# MSS_TOPRCM register map
Vendor: Texas Instruments
Peripheral module from a debugger description file (folder radar).
Registers are 32-bit, read-write, no defined reset value unless marked. A register's access mark holds for its fields unless they carry their own. Offsets are as the file gives them; lines under a group give offsets from that group; [hi:lo] are bit positions; {n}, {i} and the like mark numbered series; 'fields as' and 'values as' point back to an identical list; <NAME> marks a mode.

## MSS_TOPRCM
0x08 BSSCTL — Control Signals to BSS
  [31:24] BSSCPUHALT — Halt BSS CR4, To halt : either 3:0 should be 0xD or 7:4 should be 0xA One should Halt the processor before releasing BSS reset.
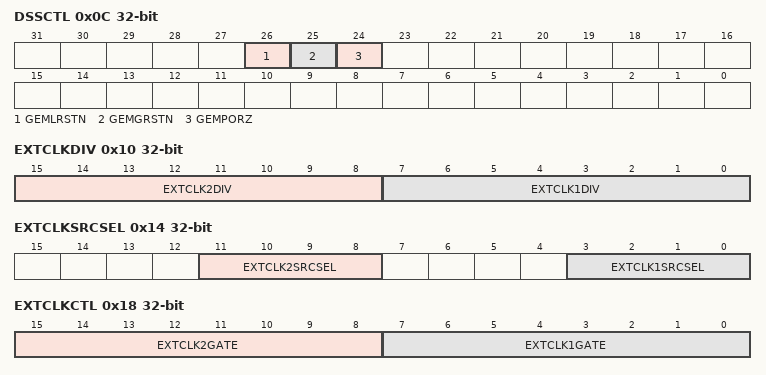
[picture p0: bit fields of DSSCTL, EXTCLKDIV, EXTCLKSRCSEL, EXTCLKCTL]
0x0C DSSCTL — Control Signals to DSS
  [26] GEMLRSTN — DSP Local Reset value that will be propagated to the DSP when the DSP Power FSM has switched the DSP on. 0x0 : Reset is asserted 0x1 : Reset is deasserted This value is to be set by SW to 0x1 once initially before the DSP is powered on and is not expected to be changed. All Reset toggling for the DSP is exepcted to be done via the DSP Power FSM and the DSP STC FSM
  [25] GEMGRSTN — DSP Global Reset value that will be propagated to the DSP when the DSP Power FSM has switched the DSP on. 0x0 : Reset is asserted 0x1 : Reset is deasserted This value is to be set by SW to 0x1 once initially before the DSP is powered on and is not expected to be changed. All Reset toggling for the DSP is exepcted to be done via the DSP Power FSM and the DSP STC FSM
  [24] GEMPORZ — DSP Por Reset value that will be propagated to the DSP when the DSP Power FSM has switched the DSP on. 0x0 : Reset is asserted 0x1 : Reset is deasserted This value is to be set by SW to 0x1 once initially before the DSP is powered on and is not expected to be changed. All Reset toggling for the DSP is exepcted to be done via the DSP Power FSM and the DSP STC FSM
0x10 EXTCLKDIV — Clock divide value for MCU_CLKOUT and PMIC_CLKOUT
  [15:8] EXTCLK2DIV — Divide value for clock source ( selected by field EXTCLKSRCSEL in register CLKSRCSEL.) to PMIC_CLKOUT generation logic “0000_0000” => div1 “0000_0001” => div2 | | “1111_1111” => div256 One Should change the divide value before switching to New clock. Switching to New clock is done by progrmming EXTCLK2SRCSEL.
  [7:0] EXTCLK1DIV — Divide value for MCU_CLKOUT (the one going out of chip) source clock selected by field EXTCLKSRCSEL in register CLKSRCSEL. “0000_0000” => div1 “0000_0001” => div2 | | “1111_1111” => div256 One Should change the divide value before switching to New clock. Switching to New clock is done by progrmming EXTCLK1SRCSEL.
0x14 EXTCLKSRCSEL — Clock source select value for MCU_CLKOUT and PMIC_CLKOUT
  [11:8] EXTCLK2SRCSEL — Select clock source for PMIC_CLKOUT generation “000” => CPUCLK from ANA(XTAL 40Mhz or 50 Mhz or 80Mh or 100Mhz/ RCCLK in WU limp mode) “001” => RCCLK (10Mhz) “010” => 600Mhz PLL divided clock “011” => 240Mhz PLL divided clock “100” => RCCLK (10Mhz) “101” => RCCLK (10Mhz) “110” => REFCLK from ANA (40Mhz or 50 Mhz or 80Mh or 100Mhz) “111” => RCCLK
  [3:0] EXTCLK1SRCSEL — Select clock source for MCU_CLKOUT “000” =>CPUCLK from ANA(XTAL 40Mhz or 50 Mhz or 80Mh or 100Mhz/ RCCLK in WU limp mode) “001” => RCCLK (10Mhz) “010” => 600Mhz PLL divided clock “011” => 240Mhz PLL divided clock “100” => RCCLK (10Mhz) “101” => RCCLK (10Mhz) “110” => REFCLK from ANA (40Mhz or 50 Mhz or 80Mh or 100Mhz) “111” => RCCLK
0x18 EXTCLKCTL — Clock gate control for MCU_CLKOUT and PMIC_CLKOUT
  [15:8] EXTCLK2GATE — Pre clock divider gate for PMIC_CLKOUT. Gates the clock before divider. to gate the clock either 3:0 should be 0xD or 7:4 should be 0xA
  [7:0] EXTCLK1GATE — Pre clock divider gate for MCU_CLKOUT. Gates the clock before divider. to gate the clock either 3:0 should be 0xD or 7:4 should be 0xA
0x1C SOFTSYSRST — Software triggered Warm Reset
  [7:0] SOFTSYSRST — Write 0xAD to trigger warm reset to the chip.
0x20 WDRSTEN — Issue Warm reset upon MSS Watch dog reset
  [7:0] WDRSTEN — Write 0xAD to trigger warm reset to the chip upon MSS wdog reset.
0x24 SYSRSTCAUSE ro — Reset cause register
  [3:0] SYSRSTCAUSE — Gives cause of chip reset “1001” : System out of NRESET “1010” : Warm reset because of MSS Wdog. “1100” : Warm reset because of Software trigger- SOFTSYSRST “1000” : External Warm Reset
0x28 SYSRSTCAUSECLR access not given — Clear Reset Cause register
  [7:0] SYSRSTCAUSECLR — Write 0xAD to clear SYSRSTCAUSE..Self clearing
0x34 MISCCAPT ro — Capture required Status values across the chip.
  [31:0] MISCCAPT — 4:0 :TI_EFC_ERR. 00000 : No Error 00001 Time-out 00010 Autoload: Not enough FuseROM data 00011 Autoload: Wrong scan chain signature 00100 Autoload: Interrupted 10100 Program: Dumpword: Test ROM: Interrupted 00101 Autoload: Two-bit error detected 00110 program: Write protect set 00111 Program: Too many data write iterations 01000 Program: Too many control bit iterations 01001 Test unprogrammed FuseROM: Bit set 01010 Redundant repair row 01011 Program: Too many CRA write iterations 01100 Program: Program done 01101 Program: Compare skip 01110 Program: Abort 01111 Program with incorrect key register value 10000 Autoload: FuseROM LASTROW stuck 10010 FuseROM LASTROW stuck 10101 Autoload: one-bit errorDetected 10110 Dump Word: two-bit error Detected 10111 Dump Word: one-bit error Detected 11000 Self-test error detected 11111 - 11001 Not assigned 5: BSS reset got asserted upon setting BSSPRST/BSSRST. 6: DSS reset got asserted upon setting DSSPRST/DSSRST [11:7] : CUST_EFC_ERR.Description same as TI_EFC_ERR
0x38 DCDCCTL0 — PMIC_CLKOUT dethering control
  [31:0] DCDCCTL0 — [26:0] PMIC_CLKOUT Frequency slope value.Unsigned
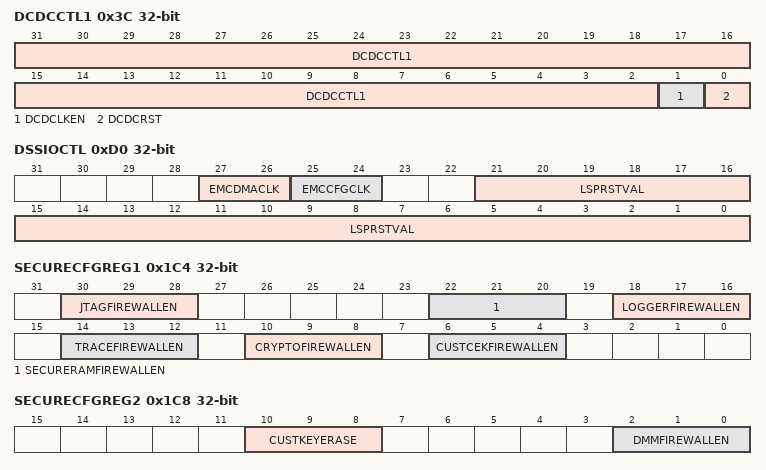
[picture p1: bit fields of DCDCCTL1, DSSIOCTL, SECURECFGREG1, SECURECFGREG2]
0x3C DCDCCTL1 — PMIC_CLKOUT dethering control
  [31:2] DCDCCTL1 — PMIC_CLKOUT dithering control [8] : Frequency accumulation Mode . ‘0’ : Continous mode.’1’ : Staircase mode [9] : ‘1’ Enables dither [23:16] : Minimum frequency threshold [31:24] : Maximum frequency threshold
  [1] DCDCLKEN — PMIC_CLKOUT Enable – Multi Bit
  [0] DCDCRST — PMIC_CLKOUT dithering control block reset (active high) – Multi Bit
0x48 USERMODEEN
  [31:0] USERMODEEN — Write 0XADADADAD to enable user mode write access to TOP RCM space from 0x00 to 0XFF
0x4C LVDSPADCTL0 — LVDS pad control
  [31:0] LVDSPADCTL0 — 0 : pwrdn Control for i_LVDSclk_io_cell 1 : lopwra Control for i_LVDSclk_io_cell 2 : lopwrb Control for i_LVDSclk_io_cell 3 : lpsel Control for i_LVDSclk_io_cell 4 : sub_lvds_en Control for i_LVDSclk_io_cell 5 : hiz_disable Control for i_LVDSclk_io_cell 6 : ext_res_en Control for i_LVDSclk_io_cell 7 : Reserved 8 : pwrdn Control for i_LVDS_tx0_io_cell 9 : lopwra Control for i_LVDS_tx0_io_cell 10 : lopwrb Control for i_LVDS_tx0_io_cell 11 : lpsel Control for i_LVDS_tx0_io_cell 12 : sub_lvds_en Control for i_LVDS_tx0_io_cell 13 : hiz_disable Control for i_LVDS_tx0_io_cell 14 : ext_res_en Control for i_LVDS_tx0_io_cell 15 : Reserved 16 : pwrdn Control for i_LVDS_tx1_io_cell 17 : lopwra Control for i_LVDS_tx1_io_cell 18 : lopwrb Control for i_LVDS_tx1_io_cell 19 : lpsel Control for i_LVDS_tx1_io_cell 20 : sub_lvds_en Control for i_LVDS_tx1_io_cell 21 : hiz_disable Control for i_LVDS_tx1_io_cell 22 : ext_res_en Control for i_LVDS_tx1_io_cell 23 -31 : Reserved
0x50 LVDSPADCTL1 — LVDS pad control
  [31:0] LVDSPADCTL1 — 0- 7 : Reserved 8 : pwrdn Control for i_LVDSfrclk_io_cell 9 : lopwra Control for i_LVDSfrclk_io_cell 10 : lopwrb Control for i_LVDSfrclk_io_cell 11 : lpsel Control for i_LVDSfrclk_io_cell 12 : sub_lvds_en Control for i_LVDSfrclk_io_cell 13 : hiz_disable Control for i_LVDSfrclk_io_cell 14 : ext_res_en Control for i_LVDSfrclk_io_cell 15-23: Reserved 24 : pwrdn Control for lvds_bias_cell 25 : set Control for lvds_bias_cell
0x60 DFTREG0
  [31:0] DFTREG0 — TRM Description: [3:0] : MSS PBIST SELFTEST KEY = 4'b1010 [4] : Reserved [5] : PBIST IP reset control. 1 = reset, 0 = out of reset. The PBIST_SELFTEST_KEY has to enabled in order to program this bit. [31:6] : Write 1'b1 to a bit to configure a particular memory group for Self-Test, and 1'b0 to disable a particular memory group 16XX Description: [3:0] : MSS PBIST SELFTEST KEY = 4'b1010 [4] : Reserved [5] : PBIST IP reset control. 1 = reset, 0 = out of reset. The PBIST_SELFTEST_KEY has to enabled in order to program this bit. [6] : MSS DCAN and CANFD RAMs - Write 1'b1 to configure this memory group for self-test [7] : MSS DMA RAMs - Write 1'b1 to configure this memory group for self-test [8] : MSS VIM RAMs - Write 1'b1 to configure this memory group for self-test [9] : MSS SWBUF RAM - Write 1'b1 to configure this memory group for self-test [10] : MSS TCMAROMs - Write 1'b1 to configure this memory group for self-test [11] : MSS TCMA RAMs - Write 1'b1 to configure this memory group for self-test [12] : MSS TCMB RAMs - Write 1'b1 to configure this memory group for self-test [13] : Reserved [14] : MSS L3SHARED RAMs BANK2 and BANK3 - Write 1'b1 to configure this memory group for self-test [15] : MSS L3SHARED RAMs BANK4 and BANK5 - Write 1'b1 to configure this memory group for self-test [16] : MSS SPIA RAMs - Write 1'b1 to configure this memory group for self-test [17] : MSS SPIB RAMs - Write 1'b1 to configure this memory group for self-test [18] : MSS MBOX RAMs - Write 1'b1 to configure this memory group for self-test [19] : MSS CR4 STC ROM - Write 1'b1 to configure this memory group for self-test [20] : Reserved [21] : Reserved [22] : Reserved [23] : Reserved [24] : DSS ADCBUF RAMs - Write 1'b1 to configure this memory group for self-test [25] : DSS FFTACC RAMs - Write 1'b1 to configure this memory group for self-test [26] : DSS TPCC RAMs - Write 1'b1 to configure this memory group for self-test [27] : DSS CBUF DATA and ECC RAMs - Write 1'b1 to configure this memory group for self-test [28] : Reserved [29] : DSS CQ RAMs- Write 1'b1 to configure this memory group for self-test [30] : BSS TCMAROMs - Write 1'b1 to configure this memory group for self-test [31] : BSS TCMA and TCMB RAMs - Write 1'b1 to configure this memory group for self-test
0x64 DFTREG1
  [31:0] DFTREG1 — TRM Description: [31:0] : Write 1'b1 to a bit to configure a particular memory group for Self-Test, and 1'b0 to disable a particular memory group 16XX Description: [0] : BSS FFT RAMs and ROM - Write 1'b1 to configure this memory group for self-test [1] : BSS VIM RAMs - Write 1'b1 to configure this memory group for self-test [2] : BSS DFE RAMs - Write 1'b1 to configure this memory group for self-test [3] : BSS CR4 STC ROM - Write 1'b1 to configure this memory group for self-test [4] : BSS DFE STC ROM - Write 1'b1 to configure this memory group for self-test [5] : BSS GPADC RAMs - Write 1'b1 to configure this memory group for self-test [12:6] : Reserved [13] : DSS HS and DATA_TR RAMs - Write 1'b1 to configure this memory group for self-test [14] : DSS FIR RAM - Write 1'b1 to configure this memory group for self-test [15] : GEM STC ROM - Write 1'b1 to configure this memory group for self-test [16] : GEM PBIST ROM - Write 1'b1 to configure this memory group for self-test [17] : GEM CPBPM RAMs - Write 1'b1 to configure this memory group for self-test [18] : Reserved [19] : Reserved [19] : MSS SECUREKEY RAM - Write 1'b1 to configure this memory group for self-test [21] : MSS TRACEBUF RAM - Write 1'b1 to configure this memory group for self-test [31:22] : Reserved
0x68 DFTREG2
  [31:0] DFTREG2 — TI Internal Register.Reserved for HW RnD
0x74 DFTREG5
  [31:0] DFTREG5 — TRM Description: [0] : Reserved [4:1] DSP PBIST SELFTEST KEY = 4'b1010 [8:5]: Sub-system level memory Self-Test power clock gate enable controls [31:9] : Reserved 16XX Description: [0] : Reserved [4:1] DSP PBIST SELFTEST KEY = 4'b1010 [5]: Write 1'b1 to enable BSS Memory Self-Test Power Clock gate [6]: Write 1'b1 to enable MSS Memory Self-Test Power Clock gate [7]: Write 1'b1 to enable DSS Memory Self-Test Power Clock gate [8]: Write 1'b1 to enable GEM-L2 Memory Self-Test Power Clock gate [31:9] : Reserved
0xD0 DSSIOCTL — DSS Tie offs
  [27:26] EMCDMACLK — Static register for DSP.Should be programmed before DSP powerup. When DSP clock =600Mhz, program EMCDMACLK=1 When DSP clock =400Mhz, program EMCDMACLK=0
  [25:24] EMCCFGCLK — Static register for DSP.Should be programmed before DSP powerup. When DSP clock =600Mhz, program EMCCFGCLK=1 When DSP clock =400Mhz, program EMCCFGCLK=0
  [21:0] LSPRSTVAL — ISTP reset value. Used as the 22 MSBs of the 32-bit initial fetch address. Can be be set to any GEM-accessible address in the memory map. Tyipcally set to L1P RAM or ROM, L2 RAM or ROM, or chip-level RAM or ROM, including EMIF address range.
{0xEC+4i} SPARE{i} (i=0..3) — Spare Register
  [31:0] SPARE{i} — Spare register for FW use
0xFC MSS_SIGNATURE — Spare Register
0x114 REG00 ro — Device Specific information
  [25:0] Device_Specific_REG00 — Device Specific information - see errata
0x158 GEMBOOTSTCEN
  [0] GEMBOOTSTCEN — ‘1’ : Enable GEM STC during GEM power UP
0x180 USERMODEEN2
  [31:0] USERMODEEN2 — Write 0XADADADAD to enable user mode write access to TOP RCM space which are resettable only by Power on reset. i.e. from offset address 0x100 to 0x1FF
0x18C SYSTICK ro
  [31:0] SYSTICK — Continuous counter running on 32Khz derived from RC clock.
0x1C4 SECURECFGREG1
  [30:28] JTAGFIREWALLEN — JTAG Firewall.Firewall Disabled for value "111" and enabled for rest
  [22:20] SECURERAMFIREWALLEN — Set Secure RAM Firewall.Firewall Disabled for value "111" and enabled for rest
  [18:16] LOGGERFIREWALLEN — Set Logger Firewall.Firewall Disabled for value "111" and enabled for rest
  [14:12] TRACEFIREWALLEN — Set Trace Firewall. Firewall Disabled for value "111" and enabled for rest
  [10:8] CRYPTOFIREWALLEN — Set Crypto Firewall. Firewall Disabled for value "111" and enabled for rest
  [6:4] CUSTCEKFIREWALLEN — Set CEK1,CEK2 firewall.Firewall Disabled for value "111" and enabled for rest
0x1C8 SECURECFGREG2
  [10:8] CUSTKEYERASE — Erase CEK1 ,CEK2,CPK Keys when value "111" is written
  [2:0] DMMFIREWALLEN — DMM Firewall.Firewall Disabled for value "111" and enabled for rest
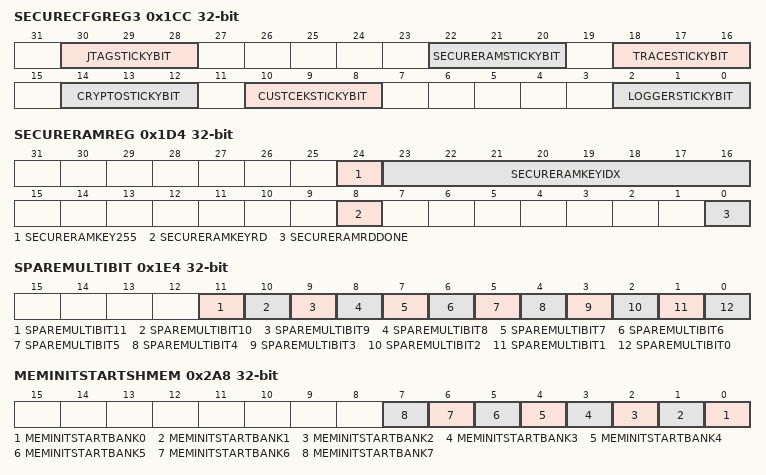
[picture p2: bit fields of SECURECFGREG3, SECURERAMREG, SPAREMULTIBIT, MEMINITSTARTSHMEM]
0x1CC SECURECFGREG3
  [30:28] JTAGSTICKYBIT — JTAG Sticky Reg. Sticky reg is set when value "111 is written
  [22:20] SECURERAMSTICKYBIT — Secure RAM Sticky Reg. Sticky reg is set when value "111 is written
  [18:16] TRACESTICKYBIT — Trace Sticky Reg. Sticky reg is set when value "111 is written
  [14:12] CRYPTOSTICKYBIT — Crypto Sticky Reg. Sticky reg is set when value "111 is written
  [10:8] CUSTCEKSTICKYBIT — CEK1,CEK2 Sticky Reg for firewall. Sticky reg is set when value "111 is written
  [2:0] LOGGERSTICKYBIT — Logger Sticky Reg. Sticky reg is set when value "111 is written
0x1D0 SECURECFGREG4
  [2:0] DMMSTICKYBIT — DMM Sticky Reg. Sticky reg is set when value "111 is written
0x1D4 SECURERAMREG access not given
  [24] SECURERAMKEY255 rw — 1: Secure RAM key bitwidth = 255 0:Secure RAM key bitwidth = 128
  [23:16] SECURERAMKEYIDX rw — Index to Secure RAM
  [8] SECURERAMKEYRD — 1: Load key from secure RAM into register to be used by AES engine.Self clearing
  [0] SECURERAMRDDONE ro — Secure RAM key loaded into register
0x1E4 SPAREMULTIBIT — Spare Register
  [11] SPAREMULTIBIT11 — MIBSPIB : when set the TRIGGER’s are un-gated only when chip-select is active
  [10] SPAREMULTIBIT10 — SPIB trigger source polarity select.’0’ - Polarity 0,’1’-Polarity 1
  [9] SPAREMULTIBIT9 — SPIA trigger source polarity select.’0’ - Polarity 0,’1’-Polarity 1
  [8] SPAREMULTIBIT8 — ‘1’: MIBSPIB External chip select is overridden with the value of MIBSPIB CS polarity-slave mode
  [7] SPAREMULTIBIT7 — ‘1’: MIBSPIA External chip select is overridden with the value of MIBSPIA CS polarity-slave mode
  [6] SPAREMULTIBIT6 — MIBSPIB CS Trigger SRC enable ‘1’: Use CS as trigger source
  [5] SPAREMULTIBIT5 — MIBSPIB CS polarity-slave mode 1: Active high 0:Active low
  [4] SPAREMULTIBIT4 — MIBSPIB MISO OE_N Control based on Chip select(CS)-applicable in slave mode 1:MISO OEN controlled based on CS.When CS is inactive OE_N=1 0:MISO OEN controlled by IP
  [3] SPAREMULTIBIT3 — MIBSPIA :When set the TRIGGER’s are un-gated only when chip-select is active.
  [2] SPAREMULTIBIT2 — MIBSPIA CS Trigger SRC enable-slave mode ‘1’: Use CS as trigger source
  [1] SPAREMULTIBIT1 — MIBSPIA CS polarity-slave mode 1: Active high 0:Active low
  [0] SPAREMULTIBIT0 — MIBSPIA MISO OE_N Control based on Chip select(CS)-applicable in slave mode 1:MISO OEN controlled based on CS.When CS is inactive OE_N=1,else controlled by IP 0:MISO OEN controlled by IP
{0x1D8+4i} SPARE{i} (i=4..9) — Spare Register
  [31:0] SPARE{i} — Spare register for FW use
0x200 UID31TO0 ro — Device Specific Implementation
0x204 UID63TO32 ro — Device Specific Implementation
0x208 UID95TO64 ro — Device Specific Implementation
0x20C UID119TO96 ro — Device Specific Implementation
0x2A8 MEMINITSTARTSHMEM access not given — Shared memory initialization start
  [n] MEMINITSTARTBANK{n} (n=0..7) — Writing '1' will trigger Shared memory initialization for bank {n}.Self clearing
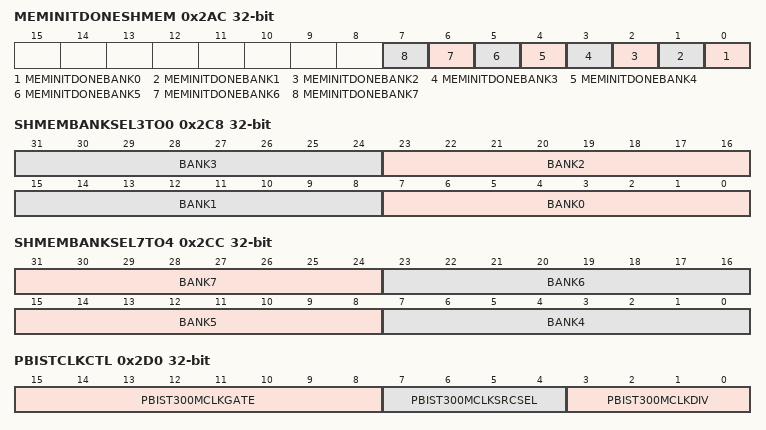
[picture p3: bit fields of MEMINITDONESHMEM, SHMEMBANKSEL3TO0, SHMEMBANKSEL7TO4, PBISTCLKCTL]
0x2AC MEMINITDONESHMEM ro — Shared memory intialization end
  [n] MEMINITDONEBANK{n} (n=0..7) — Memory Initialization done status for Shared memory for bank {n}
0x2B0 DSSMEMTAB0 — Controls ordering of banks in shared memory associated with DSS
  [31:0] DSSMEMTAB0 — DSS L3RAM memory table for shared memory. Ordering of address in shared memory. 0th 128KB address goes to bank number programmed in [3:0] of this register(default is bank 0), 1st 128KB address goes to bank number programmed in [7:4] of this register(default is bank 1), 2nd 128KB address goes to bank number programmed in [11:8] of this register(default is bank 2), 3rd 128KB address goes to bank number programmed in [15:12] of this register(default is bank 3). 4th 128KB address goes to bank number programmed in [19:16] of this register(default is bank 4), 5th 128KB address goes to bank number programmed in [23:20] of this register(default is bank 5), 6th 128KB address goes to bank number programmed in [27:24] of this register(default is bank 6), 7th 128KB address goes to bank number programmed in [31:28] of this register(default is bank 7). Corresponding banks need to be selected for DSS in SHMEMBANKSEL regsiter
0x2BC TCMAMEMTAB — Controls ordering of banks in shared memory associated with MSS TCMA
  [15:0] TCMAMEMTAB — MSS TCMA memory table for shared memory. Ordering of address in shared memory. 0th 128KB address goes to bank number programmed in [3:0] of this register(default is bank 4), 1st 128KB address goes to bank number programmed in [7:4] of this register(default is bank 5), 2nd 128KB address goes to bank number programmed in [11:8] of this register(default is bank 6), 3rd 128KB address goes to bank number programmed in [15:12] of this register(default is bank 7). Corresponding banks need to be selected for MSS TCMA in SHMEMBANKSEL regsiter
0x2C0 TCMBMEMTAB — Controls ordering of banks in shared memory associated with MSS TCMB
  [15:0] TCMBMEMTAB — MSS TCMB memory table for shared memory. Ordering of address in shared memory. 0th 128KB address goes to bank number programmed in [3:0] of this register(default is bank 4), 1st 128KB address goes to bank number programmed in [7:4] of this register(default is bank 5), 2nd 128KB address goes to bank number programmed in [11:8] of this register(default is bank 6), 3rd 128KB address goes to bank number programmed in [15:12] of this register(default is bank 7). Corresponding banks need to be selected for MSS TCMB in SHMEMBANKSEL regsiter
0x2C8 SHMEMBANKSEL3TO0 — Shared memory master allocation.Writing to each 8 bit field indicates the bank allocated to which master. 0x1 : DSS 0x2 : MSS TCMA 0x4 : MSS TCMB 0x8 : OCLA 0x10: BSS TCMA
  [8n+7:8n] BANK{n} (n=0..3) — only valid value is 0x1 else memory is not used. (Allocation only to DSS L3RAM)
0x2CC SHMEMBANKSEL7TO4 — Shared memory master allocation.Writing to each 8 bit field indicates the bank allocated to which master. 0x1 : DSS 0x2 : MSS TCMA 0x4 : MSS TCMB 0x8 : OCLA 0x10: BSS TCMA
  [31:24] BANK7 — only valid value is 0x1/0x2/0x4/0x8/0X10 else memory is not used. (Allocation to DSS L3RAM, MSS TCMA/B, OCLA,BSS TCMA)
  [23:16] BANK6 — only valid value is 0x1/0x2/0x4/0x8/0X10 else memory is not used. (Allocation to DSS L3RAM, MSS TCMA/B, OCLA,BSS TCMA)
  [15:8] BANK5 — only valid value is 0x1/0x2/0x4/0x8 else memory is not used. (Allocation to DSS L3RAM, MSS TCMA/B, OCLA)
  [7:0] BANK4 — only valid value is 0x1/0x2/0x4/0x8 else memory is not used. (Allocation to DSS L3RAM, MSS TCMA/B, OCLA)
0x2D0 PBISTCLKCTL — PBIST clock control register
  [15:8] PBIST300MCLKGATE — Pre clock divider gate for PBIST300M clock. Gates the clock before divider. to gate the clock either 3:0 should be 0xD or 7:4 should be 0xA
  [7:4] PBIST300MCLKSRCSEL — Select clock source for DSP PBIST Clock source “000” => CPUCLK from ANA(XTAL 40Mhz or 50 Mhz or 80Mh or 100Mhz/ RCCLK in WU limp mode) “001” => RCCLK (10Mhz) “010” => 600Mhz PLL divided clock “011” => 240Mhz PLL divided clock “100” => RCCLK (10Mhz) “101” => RCCLK (10Mhz) “110” => REFCLK from ANA (40Mhz or 50 Mhz or 80Mh or 100Mhz) “111” => RCCLK
  [3:0] PBIST300MCLKDIV — Divide value for DSP PBIST source clock selected by field PBIST300MCLKSRCSEL in register CLKSRCSEL. “0000” => div1 “0001” => div2 | | “1111” => div15 One Should change the divide value before switching to New clock. Switching to New clock is done by progrmming PBIST300MCLKSRCSEL
